# USART_0__UART_SPI_Mode_1 register map
Vendor: Texas Instruments
Peripheral module from a debugger description file (folder msp430).
Registers are 8-bit, access not given, no defined reset value unless marked. A register's access mark holds for its fields unless they carry their own. Offsets are as the file gives them; lines under a group give offsets from that group; [hi:lo] are bit positions; {n}, {i} and the like mark numbered series; 'fields as' and 'values as' point back to an identical list; <NAME> marks a mode.

## USART_0_UART/SPI_Mode
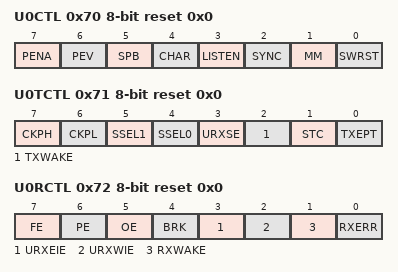
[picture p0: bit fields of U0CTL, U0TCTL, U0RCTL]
0x70 U0CTL rw reset 0x0 — USART 0 Control
  [7] PENA — Parity enable
  [6] PEV — Parity 0:odd / 1:even
  [5] SPB — Stop Bits 0:one / 1: two
  [4] CHAR — Data 0:7-bits / 1:8-bits
  [3] LISTEN — Listen mode
  [2] SYNC — UART / SPI mode
  [1] MM — Master Mode off/on
  [0] SWRST — USART Software Reset
0x71 U0TCTL rw reset 0x0 — USART 0 Transmit Control
  [7] CKPH — SPI: Clock Phase
  [6] CKPL — Clock Polarity
  [5] SSEL1 — Clock Source Select 1
  [4] SSEL0 — Clock Source Select 0
  [3] URXSE — Receive Start edge select
  [2] TXWAKE — TX Wake up mode
  [1] STC — SPI: STC enable 0:on / 1:off
  [0] TXEPT — TX Buffer empty
0x72 U0RCTL rw reset 0x0 — USART 0 Receive Control
  [7] FE — Frame Error
  [6] PE — Parity Error
  [5] OE — Overrun Error
  [4] BRK — Break detected
  [3] URXEIE — RX Error interrupt enable
  [2] URXWIE — RX Wake up interrupt enable
  [1] RXWAKE — RX Wake up detect
  [0] RXERR — RX Error Error
0x73 U0MCTL — USART 0 Modulation Control
0x74 U0BR0 — USART 0 Baud Rate 0
0x75 U0BR1 — USART 0 Baud Rate 1
0x76 U0RXBUF — USART 0 Receive Buffer
0x77 U0TXBUF — USART 0 Transmit Buffer
